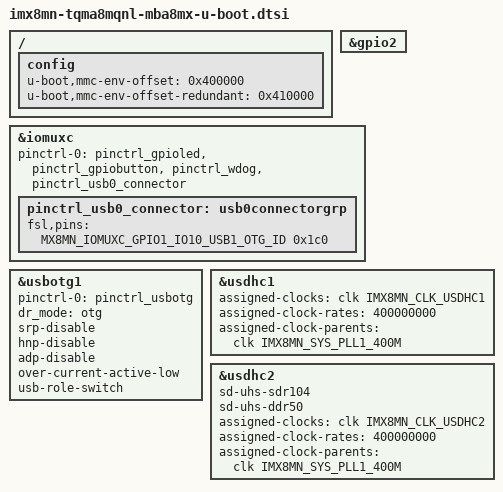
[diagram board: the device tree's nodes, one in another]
// SPDX-License-Identifier: GPL-2.0-or-later OR MIT
/*
 * Copyright (c) 2020-2023 TQ-Systems GmbH <u-boot@ew.tq-group.com>,
 * D-82229 Seefeld, Germany.
 */

#include "imx8mn-tqma8mqnl-u-boot.dtsi"
#include "mba8mx-u-boot.dtsi"

/ {
	config {
		/* 32 kiB redundant env */
		u-boot,mmc-env-offset = <0x400000>;
		u-boot,mmc-env-offset-redundant = <0x410000>;
	};
};

&gpio2 {
	/delete-node/ sel-usb-hub-hog;
};

&iomuxc {
	pinctrl-names = "default";
	pinctrl-0 = <&pinctrl_gpioled>,
		    <&pinctrl_gpiobutton>,
		    <&pinctrl_wdog>,
		    <&pinctrl_usb0_connector>;

	/*
	 * USB OTG ID to support ci_udc_otg_phy_mode
	 * needs USBNC CTRL2, bit DIG_ID_SEL configured
	 */
	pinctrl_usb0_connector: usb0connectorgrp {
		fsl,pins = <MX8MN_IOMUXC_GPIO1_IO10_USB1_OTG_ID	0x1c0>;
	};
};

&usbotg1 {
	pinctrl-names = "default";
	pinctrl-0 = <&pinctrl_usbotg>;
	dr_mode = "otg";
	srp-disable;
	hnp-disable;
	adp-disable;
	over-current-active-low;
	usb-role-switch;
	u-boot,dm-spl;
};

&usdhc1 {
	u-boot,dm-spl;
	assigned-clocks = <&clk IMX8MN_CLK_USDHC1>;
	assigned-clock-rates = <400000000>;
	assigned-clock-parents = <&clk IMX8MN_SYS_PLL1_400M>;
};

&usdhc2 {
	u-boot,dm-spl;
	sd-uhs-sdr104;
	sd-uhs-ddr50;
	assigned-clocks = <&clk IMX8MN_CLK_USDHC2>;
	assigned-clock-rates = <400000000>;
	assigned-clock-parents = <&clk IMX8MN_SYS_PLL1_400M>;
};

